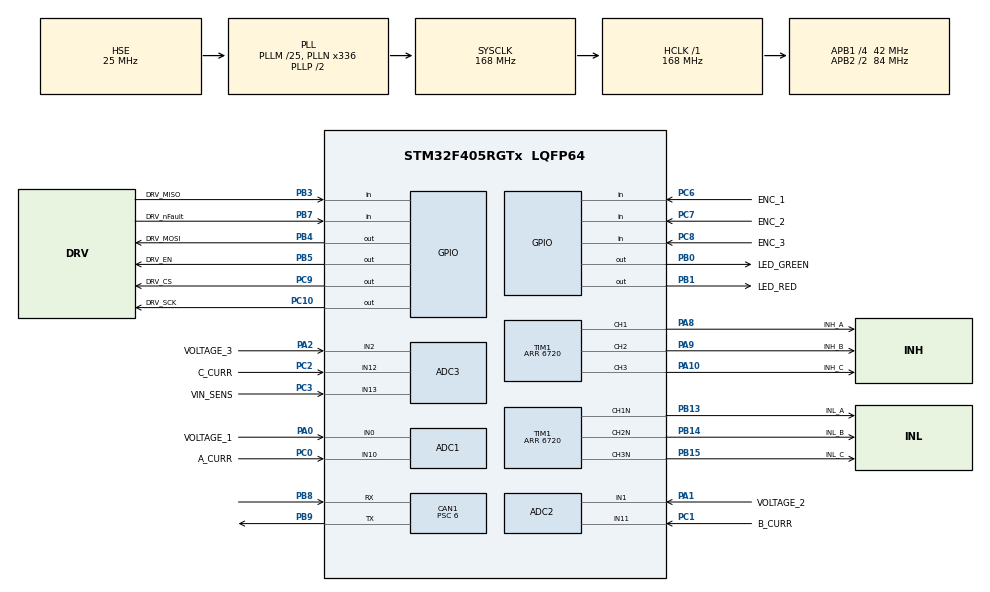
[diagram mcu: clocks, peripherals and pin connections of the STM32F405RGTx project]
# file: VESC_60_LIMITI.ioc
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ADC1.Channel-11\#ChannelInjectedConversion=ADC_CHANNEL_10
ADC1.Channel-12\#ChannelInjectedConversion=ADC_CHANNEL_10
ADC1.Channel-13\#ChannelRegularConversion=ADC_CHANNEL_VREFINT
ADC1.Channel-3\#ChannelRegularConversion=ADC_CHANNEL_10
ADC1.Channel-4\#ChannelRegularConversion=ADC_CHANNEL_0
ADC1.Channel-8\#ChannelInjectedConversion=ADC_CHANNEL_10
ADC1.ClockPrescaler=ADC_CLOCK_SYNC_PCLK_DIV6
ADC1.ExternalTrigConv=ADC_EXTERNALTRIGCONV_T2_CC2
ADC1.ExternalTrigConvEdge=ADC_EXTERNALTRIGCONVEDGE_FALLING
ADC1.InjNumberOfConversion=3
ADC1.InjectedOffset-11\#ChannelInjectedConversion=0
ADC1.InjectedOffset-12\#ChannelInjectedConversion=0
ADC1.InjectedOffset-8\#ChannelInjectedConversion=0
ADC1.InjectedRank-11\#ChannelInjectedConversion=2
ADC1.InjectedRank-12\#ChannelInjectedConversion=3
ADC1.InjectedRank-8\#ChannelInjectedConversion=1
ADC1.Mode=ADC_TRIPLEMODE_INJECSIMULT
ADC1.NbrOfConversion=3
ADC1.NbrOfConversionFlag=1
ADC1.Rank-13\#ChannelRegularConversion=3
ADC1.Rank-3\#ChannelRegularConversion=1
ADC1.Rank-4\#ChannelRegularConversion=2
ADC1.SamplingTime-11\#ChannelInjectedConversion=ADC_SAMPLETIME_3CYCLES
ADC1.SamplingTime-12\#ChannelInjectedConversion=ADC_SAMPLETIME_3CYCLES
ADC1.SamplingTime-13\#ChannelRegularConversion=ADC_SAMPLETIME_3CYCLES
ADC1.SamplingTime-3\#ChannelRegularConversion=ADC_SAMPLETIME_3CYCLES
ADC1.SamplingTime-4\#ChannelRegularConversion=ADC_SAMPLETIME_3CYCLES
ADC1.SamplingTime-8\#ChannelInjectedConversion=ADC_SAMPLETIME_3CYCLES
ADC1.ScanConvMode=ENABLE
ADC1.master=1
ADC2.Channel-0\#ChannelRegularConversion=ADC_CHANNEL_11
ADC2.Channel-1\#ChannelRegularConversion=ADC_CHANNEL_1
ADC2.Channel-5\#ChannelInjectedConversion=ADC_CHANNEL_11
ADC2.Channel-6\#ChannelInjectedConversion=ADC_CHANNEL_11
ADC2.ClockPrescaler=ADC_CLOCK_SYNC_PCLK_DIV6
ADC2.InjNumberOfConversion=2
ADC2.InjectedOffset-5\#ChannelInjectedConversion=0
ADC2.InjectedOffset-6\#ChannelInjectedConversion=0
ADC2.InjectedRank-5\#ChannelInjectedConversion=1
ADC2.InjectedRank-6\#ChannelInjectedConversion=2
ADC2.Mode=ADC_TRIPLEMODE_INJECSIMULT
ADC2.NbrOfConversion=2
ADC2.NbrOfConversionFlag=1
ADC2.Rank-0\#ChannelRegularConversion=1
ADC2.Rank-1\#ChannelRegularConversion=2
ADC2.SamplingTime-0\#ChannelRegularConversion=ADC_SAMPLETIME_3CYCLES
ADC2.SamplingTime-1\#ChannelRegularConversion=ADC_SAMPLETIME_3CYCLES
ADC2.SamplingTime-5\#ChannelInjectedConversion=ADC_SAMPLETIME_3CYCLES
ADC2.SamplingTime-6\#ChannelInjectedConversion=ADC_SAMPLETIME_3CYCLES
ADC3.Channel-0\#ChannelRegularConversion=ADC_CHANNEL_12
ADC3.Channel-1\#ChannelRegularConversion=ADC_CHANNEL_2
ADC3.Channel-5\#ChannelInjectedConversion=ADC_CHANNEL_12
ADC3.Channel-6\#ChannelInjectedConversion=ADC_CHANNEL_12
ADC3.Channel-7\#ChannelInjectedConversion=ADC_CHANNEL_12
ADC3.Channel-8\#ChannelRegularConversion=ADC_CHANNEL_13
ADC3.ClockPrescaler=ADC_CLOCK_SYNC_PCLK_DIV6
ADC3.InjNumberOfConversion=3
ADC3.InjectedOffset-5\#ChannelInjectedConversion=0
ADC3.InjectedOffset-6\#ChannelInjectedConversion=0
ADC3.InjectedOffset-7\#ChannelInjectedConversion=0
ADC3.InjectedRank-5\#ChannelInjectedConversion=1
ADC3.InjectedRank-6\#ChannelInjectedConversion=2
ADC3.InjectedRank-7\#ChannelInjectedConversion=3
ADC3.NbrOfConversion=3
ADC3.NbrOfConversionFlag=1
ADC3.Rank-0\#ChannelRegularConversion=1
ADC3.Rank-1\#ChannelRegularConversion=2
ADC3.Rank-8\#ChannelRegularConversion=3
ADC3.SamplingTime-0\#ChannelRegularConversion=ADC_SAMPLETIME_3CYCLES
ADC3.SamplingTime-1\#ChannelRegularConversion=ADC_SAMPLETIME_3CYCLES
ADC3.SamplingTime-5\#ChannelInjectedConversion=ADC_SAMPLETIME_3CYCLES
ADC3.SamplingTime-6\#ChannelInjectedConversion=ADC_SAMPLETIME_3CYCLES
ADC3.SamplingTime-7\#ChannelInjectedConversion=ADC_SAMPLETIME_3CYCLES
ADC3.SamplingTime-8\#ChannelRegularConversion=ADC_SAMPLETIME_3CYCLES
CAN1.BS1=CAN_BS1_4TQ
CAN1.BS2=CAN_BS2_2TQ
CAN1.CalculateBaudRate=1000000
CAN1.CalculateTimeBit=1000
CAN1.CalculateTimeQuantum=142.85714285714286
CAN1.Prescaler=6
Dma.ADC1.0.Direction=DMA_PERIPH_TO_MEMORY
Dma.ADC1.0.FIFOMode=DMA_FIFOMODE_DISABLE
Dma.ADC1.0.Instance=DMA2_Stream4
Dma.ADC1.0.MemDataAlignment=DMA_MDATAALIGN_HALFWORD
Dma.ADC1.0.MemInc=DMA_MINC_ENABLE
Dma.ADC1.0.Mode=DMA_CIRCULAR
Dma.ADC1.0.PeriphDataAlignment=DMA_PDATAALIGN_HALFWORD
Dma.ADC1.0.PeriphInc=DMA_PINC_DISABLE
Dma.ADC1.0.Priority=DMA_PRIORITY_HIGH
Dma.Request0=ADC1
FREERTOS.Tasks01=defaultTask,8,64,StartDefaultTask,Default,NULL,Dynamic,NULL,NULL;foc_pid,40,512,foc_pid_thread,Default,NULL,Dynamic,NULL,NULL;foc_sensor,32,256,foc_sensor_thread,Default,NULL,Dynamic,NULL,NULL;foc_comm,24,128,foc_comm_thread,Default,NULL,Dynamic,NULL,NULL
FREERTOS.configENABLE_FPU=1
FREERTOS.configMINIMAL_STACK_SIZE=64
FREERTOS.configTICK_RATE_HZ=1000
FREERTOS.configTOTAL_HEAP_SIZE=5360
Mcu.Family=STM32F4
Mcu.Name=STM32F405RGTx
Mcu.Package=LQFP64
NVIC.CAN1_RX0_IRQn=true\:5\:0\:false\:false\:true\:true\:true\:true\:true
NVIC.CAN1_TX_IRQn=true\:5\:0\:false\:false\:true\:true\:true\:true\:true
NVIC.DMA2_Stream4_IRQn=true\:5\:0\:false\:false\:true\:true\:false\:true\:true
NVIC.PriorityGroup=NVIC_PRIORITYGROUP_4
NVIC.TIM3_IRQn=true\:5\:0\:false\:false\:true\:true\:true\:true\:true
NVIC.TIM4_IRQn=true\:5\:0\:false\:false\:true\:true\:true\:true\:true
NVIC.TIM8_TRG_COM_TIM14_IRQn=true\:15\:0\:false\:false\:true\:false\:false\:true\:true
NVIC.TimeBase=TIM8_TRG_COM_TIM14_IRQn
NVIC.TimeBaseIP=TIM14
PA0-WKUP.GPIO_Label=VOLTAGE_1
PA0-WKUP.Signal=SharedAnalog_PA0
PA1.GPIO_Label=VOLTAGE_2
PA1.Signal=SharedAnalog_PA1
PA10.GPIO_Label=INH_C
PA10.Signal=S_TIM1_CH3
PA13.Mode=Serial_Wire
PA13.Signal=SYS_JTMS-SWDIO
PA14.Mode=Serial_Wire
PA14.Signal=SYS_JTCK-SWCLK
PA2.GPIO_Label=VOLTAGE_3
PA2.Signal=SharedAnalog_PA2
PA8.GPIO_Label=INH_A
PA8.Signal=S_TIM1_CH1
PA9.GPIO_Label=INH_B
PA9.Signal=S_TIM1_CH2
PB0.GPIO_Label=LED_GREEN
PB0.Signal=GPIO_Output
PB1.GPIO_Label=LED_RED
PB1.Signal=GPIO_Output
PB13.GPIO_Label=INL_A
PB13.Mode=PWM Generation1 CH1 CH1N
PB13.Signal=TIM1_CH1N
PB14.GPIO_Label=INL_B
PB14.Mode=PWM Generation2 CH2 CH2N
PB14.Signal=TIM1_CH2N
PB15.GPIO_Label=INL_C
PB15.Mode=PWM Generation3 CH3 CH3N
PB15.Signal=TIM1_CH3N
PB3.GPIO_Label=DRV_MISO
PB3.Signal=GPIO_Input
PB4.GPIO_Label=DRV_MOSI
PB4.Signal=GPIO_Output
PB5.GPIO_Label=DRV_EN
PB5.Signal=GPIO_Output
PB7.GPIO_Label=DRV_nFault
PB7.GPIO_PuPd=GPIO_PULLUP
PB7.Signal=GPIO_Input
PB8.Mode=CAN_Activate
PB8.Signal=CAN1_RX
PB9.Mode=CAN_Activate
PB9.Signal=CAN1_TX
PC0.GPIO_Label=A_CURR
PC0.Signal=ADCx_IN10
PC1.GPIO_Label=B_CURR
PC1.Signal=ADCx_IN11
PC10.GPIO_Label=DRV_SCK
PC10.Signal=GPIO_Output
PC2.GPIO_Label=C_CURR
PC2.Signal=ADCx_IN12
PC3.GPIO_Label=VIN_SENS
PC3.Signal=ADCx_IN13
PC6.GPIO_Label=ENC_1
PC6.GPIO_PuPd=GPIO_PULLUP
PC6.Signal=GPIO_Input
PC7.GPIO_Label=ENC_2
PC7.GPIO_PuPd=GPIO_PULLUP
PC7.Signal=GPIO_Input
PC8.GPIO_Label=ENC_3
PC8.GPIO_PuPd=GPIO_PULLUP
PC8.Signal=GPIO_Input
PC9.GPIO_Label=DRV_CS
PC9.Signal=GPIO_Output
PH0-OSC_IN.Mode=HSE-External-Oscillator
PH0-OSC_IN.Signal=RCC_OSC_IN
PH1-OSC_OUT.Mode=HSE-External-Oscillator
PH1-OSC_OUT.Signal=RCC_OSC_OUT
ProjectManager.HeapSize=0x200
ProjectManager.StackSize=0x400
ProjectManager.TargetToolchain=MDK-ARM V5.32
RCC.48MHZClocksFreq_Value=84000000
RCC.AHBFreq_Value=168000000
RCC.APB1CLKDivider=RCC_HCLK_DIV4
RCC.APB1Freq_Value=42000000
RCC.APB1TimFreq_Value=84000000
RCC.APB2CLKDivider=RCC_HCLK_DIV2
RCC.APB2Freq_Value=84000000
RCC.APB2TimFreq_Value=168000000
RCC.CortexFreq_Value=168000000
RCC.HCLKFreq_Value=168000000
RCC.HSE_VALUE=25000000
RCC.HSI_VALUE=16000000
RCC.LSE_VALUE=32768
RCC.PLLM=25
RCC.PLLN=336
RCC.PLLSourceVirtual=RCC_PLLSOURCE_HSE
RCC.SYSCLKFreq_VALUE=168000000
RCC.SYSCLKSource=RCC_SYSCLKSOURCE_PLLCLK
RCC.VCOOutputFreq_Value=336000000
SH.ADCx_IN10.0=ADC1_IN10,IN10
SH.ADCx_IN11.0=ADC2_IN11,IN11
SH.ADCx_IN12.0=ADC3_IN12,IN12
SH.ADCx_IN13.0=ADC3_IN13,IN13
SH.S_TIM1_CH1.0=TIM1_CH1,PWM Generation1 CH1 CH1N
SH.S_TIM1_CH2.0=TIM1_CH2,PWM Generation2 CH2 CH2N
SH.S_TIM1_CH3.0=TIM1_CH3,PWM Generation3 CH3 CH3N
SH.SharedAnalog_PA0.0=GPIO_Analog
SH.SharedAnalog_PA0.1=ADC1_IN0,IN0
SH.SharedAnalog_PA1.0=GPIO_Analog
SH.SharedAnalog_PA1.1=ADC2_IN1,IN1
SH.SharedAnalog_PA2.0=GPIO_Analog
SH.SharedAnalog_PA2.1=ADC3_IN2,IN2
TIM1.Channel-PWM\ Generation1\ CH1\ CH1N=TIM_CHANNEL_1
TIM1.Channel-PWM\ Generation2\ CH2\ CH2N=TIM_CHANNEL_2
TIM1.Channel-PWM\ Generation3\ CH3\ CH3N=TIM_CHANNEL_3
TIM1.CounterMode=TIM_COUNTERMODE_CENTERALIGNED1
TIM1.DeadTime=60
TIM1.OCIdleState_1=TIM_OCIDLESTATE_RESET
TIM1.OCIdleState_2=TIM_OCIDLESTATE_RESET
TIM1.OCIdleState_3=TIM_OCIDLESTATE_RESET
TIM1.OCNIdleState_1=TIM_OCNIDLESTATE_RESET
TIM1.OCNIdleState_2=TIM_OCNIDLESTATE_RESET
TIM1.OCNIdleState_3=TIM_OCNIDLESTATE_RESET
TIM1.OffStateIDLEMode=TIM_OSSI_ENABLE
TIM1.OffStateRunMode=TIM_OSSR_ENABLE
TIM1.Period=6720
TIM1.TIM_MasterOutputTrigger=TIM_TRGO_UPDATE
TIM1.TIM_MasterSlaveMode=TIM_MASTERSLAVEMODE_ENABLE
TIM2.AutoReloadPreload=TIM_AUTORELOAD_PRELOAD_ENABLE
TIM2.Channel-PWM\ Generation1\ No\ Output=TIM_CHANNEL_1
TIM2.Channel-PWM\ Generation2\ No\ Output=TIM_CHANNEL_2
TIM2.Channel-PWM\ Generation3\ No\ Output=TIM_CHANNEL_3
TIM2.Pulse-PWM\ Generation1\ No\ Output=250
TIM2.Pulse-PWM\ Generation2\ No\ Output=250
TIM2.Pulse-PWM\ Generation3\ No\ Output=250
TIM2.TIM_MasterSlaveMode=TIM_MASTERSLAVEMODE_ENABLE
TIM4.Period=100-1
TIM4.Prescaler=84-1
TIM5.Prescaler=6-1
VP_ADC1_Vref_Input.Mode=IN-Vrefint
VP_FREERTOS_VS_CMSIS_V2.Mode=CMSIS_V2
VP_SYS_VS_tim14.Mode=TIM14
VP_TIM1_VS_ClockSourceINT.Mode=Internal
VP_TIM2_VS_ClockSourceINT.Mode=Internal
VP_TIM2_VS_ClockSourceITR.Mode=TriggerSource_ITR0
VP_TIM2_VS_ControllerModeReset.Mode=Reset Mode
VP_TIM2_VS_no_output1.Mode=PWM Generation1 No Output
VP_TIM2_VS_no_output2.Mode=PWM Generation2 No Output
VP_TIM2_VS_no_output3.Mode=PWM Generation3 No Output
VP_TIM3_VS_ClockSourceINT.Mode=Internal
VP_TIM4_VS_ClockSourceINT.Mode=Internal
VP_TIM5_VS_ClockSourceINT.Mode=Internal
board=custom

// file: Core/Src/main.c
/* USER CODE BEGIN Header */
/**
  ******************************************************************************
  * @file           : main.c
  * @brief          : Main program body
  ******************************************************************************
  * @attention
  *
  * Copyright (c) 2025 STMicroelectronics.
  * All rights reserved.
  *
  * This software is licensed under terms that can be found in the LICENSE file
  * in the root directory of this software component.
  * If no LICENSE file comes with this software, it is provided AS-IS.
  *
  ******************************************************************************
  */
/* USER CODE END Header */
#include "main.h"
#include "cmsis_os.h"
#include "adc.h"
#include "can.h"
#include "dma.h"
#include "tim.h"
#include "gpio.h"

/* USER CODE BEGIN Includes */
#include "can_bsp.h"
#include "foc_interface.h"
/* USER CODE END Includes */

void SystemClock_Config(void);
void MX_FREERTOS_Init(void);

int main(void)
{

  /* MCU Configuration--------------------------------------------------------*/

  /* Reset of all peripherals, Initializes the Flash interface and the Systick. */
  HAL_Init();

  /* Configure the system clock */
  SystemClock_Config();

  /* Initialize all configured peripherals */
  MX_GPIO_Init();
  MX_DMA_Init();
  MX_ADC1_Init();
  MX_ADC2_Init();
  MX_ADC3_Init();
  MX_TIM3_Init();
  MX_TIM1_Init();
  MX_TIM2_Init();
  MX_CAN1_Init();
  MX_TIM5_Init();
  MX_TIM4_Init();
  /* USER CODE BEGIN 2 */
  // enc_as504x_init(&as5047_cfg);
  CAN_Init(&hcan1);
  foc_init();

  /* USER CODE END 2 */

  /* Init scheduler */
  osKernelInitialize();

  /* Call init function for freertos objects (in freertos.c) */
  MX_FREERTOS_Init();

  /* Start scheduler */
  osKernelStart();

  /* We should never get here as control is now taken by the scheduler */
  /* Infinite loop */
  while (1)
  {

  }
}

void SystemClock_Config(void)
{
  RCC_OscInitTypeDef RCC_OscInitStruct = {0};
  RCC_ClkInitTypeDef RCC_ClkInitStruct = {0};

  /** Configure the main internal regulator output voltage
  */
  __HAL_RCC_PWR_CLK_ENABLE();
  __HAL_PWR_VOLTAGESCALING_CONFIG(PWR_REGULATOR_VOLTAGE_SCALE1);

  /** Initializes the RCC Oscillators according to the specified parameters
  * in the RCC_OscInitTypeDef structure.
  */
  RCC_OscInitStruct.OscillatorType = RCC_OSCILLATORTYPE_HSE;
  RCC_OscInitStruct.HSEState = RCC_HSE_ON;
  RCC_OscInitStruct.PLL.PLLState = RCC_PLL_ON;
  RCC_OscInitStruct.PLL.PLLSource = RCC_PLLSOURCE_HSE;
  RCC_OscInitStruct.PLL.PLLM = 25;
  RCC_OscInitStruct.PLL.PLLN = 336;
  RCC_OscInitStruct.PLL.PLLP = RCC_PLLP_DIV2;
  RCC_OscInitStruct.PLL.PLLQ = 4;
  if (HAL_RCC_OscConfig(&RCC_OscInitStruct) != HAL_OK)
  {
    Error_Handler();
  }

  /** Initializes the CPU, AHB and APB buses clocks
  */
  RCC_ClkInitStruct.ClockType = RCC_CLOCKTYPE_HCLK|RCC_CLOCKTYPE_SYSCLK
                              |RCC_CLOCKTYPE_PCLK1|RCC_CLOCKTYPE_PCLK2;
  RCC_ClkInitStruct.SYSCLKSource = RCC_SYSCLKSOURCE_PLLCLK;
  RCC_ClkInitStruct.AHBCLKDivider = RCC_SYSCLK_DIV1;
  RCC_ClkInitStruct.APB1CLKDivider = RCC_HCLK_DIV4;
  RCC_ClkInitStruct.APB2CLKDivider = RCC_HCLK_DIV2;

  if (HAL_RCC_ClockConfig(&RCC_ClkInitStruct, FLASH_LATENCY_5) != HAL_OK)
  {
    Error_Handler();
  }
}

void HAL_TIM_PeriodElapsedCallback(TIM_HandleTypeDef *htim)
{
  /* USER CODE BEGIN Callback 0 */
  if (htim->Instance == TIM4) {
    interface_encoder_routine();
  }

  /* USER CODE END Callback 0 */
  if (htim->Instance == TIM14) {
    HAL_IncTick();
  }
}

void Error_Handler(void)
{
  __disable_irq();
  while (1)
  {
  }
}

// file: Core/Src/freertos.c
/* USER CODE BEGIN Header */
/**
  ******************************************************************************
  * File Name          : freertos.c
  * Description        : Code for freertos applications
  ******************************************************************************
  * @attention
  *
  * Copyright (c) 2025 STMicroelectronics.
  * All rights reserved.
  *
  * This software is licensed under terms that can be found in the LICENSE file
  * in the root directory of this software component.
  * If no LICENSE file comes with this software, it is provided AS-IS.
  *
  ******************************************************************************
  */
/* USER CODE END Header */

#include "FreeRTOS.h"
#include "task.h"
#include "main.h"
#include "cmsis_os.h"

/* USER CODE BEGIN Includes */
#include "foc_interface.h"
/* USER CODE END Includes */

/* Definitions for defaultTask */
osThreadId_t defaultTaskHandle;
const osThreadAttr_t defaultTask_attributes = {
  .name = "defaultTask",
  .stack_size = 64 * 4,
  .priority = (osPriority_t) osPriorityLow,
};
/* Definitions for foc_pid */
osThreadId_t foc_pidHandle;
const osThreadAttr_t foc_pid_attributes = {
  .name = "foc_pid",
  .stack_size = 512 * 4,
  .priority = (osPriority_t) osPriorityHigh,
};
/* Definitions for foc_sensor */
osThreadId_t foc_sensorHandle;
const osThreadAttr_t foc_sensor_attributes = {
  .name = "foc_sensor",
  .stack_size = 256 * 4,
  .priority = (osPriority_t) osPriorityAboveNormal,
};
/* Definitions for foc_comm */
osThreadId_t foc_commHandle;
const osThreadAttr_t foc_comm_attributes = {
  .name = "foc_comm",
  .stack_size = 128 * 4,
  .priority = (osPriority_t) osPriorityNormal,
};

void StartDefaultTask(void *argument);
void foc_pid_thread(void *argument);
void foc_sensor_thread(void *argument);
void foc_comm_thread(void *argument);

void MX_FREERTOS_Init(void); /* (MISRA C 2004 rule 8.1) */

void MX_FREERTOS_Init(void) {

  /* Create the thread(s) */
  /* creation of defaultTask */
  defaultTaskHandle = osThreadNew(StartDefaultTask, NULL, &defaultTask_attributes);

  /* creation of foc_pid */
  foc_pidHandle = osThreadNew(foc_pid_thread, NULL, &foc_pid_attributes);

  /* creation of foc_sensor */
  foc_sensorHandle = osThreadNew(foc_sensor_thread, NULL, &foc_sensor_attributes);

  /* creation of foc_comm */
  foc_commHandle = osThreadNew(foc_comm_thread, NULL, &foc_comm_attributes);

}

void StartDefaultTask(void *argument)
{
  for(;;)
  {
    osDelay(1);
  }
}

void foc_pid_thread(void *argument)
{
  /* USER CODE BEGIN foc_pid_thread */
  /* Infinite loop */
  for(;;)
  {
    interface_run_pid();
    osDelay(1);
  }
  /* USER CODE END foc_pid_thread */
}

void foc_sensor_thread(void *argument)
{
  for(;;)
  {
    osDelay(1);
  }
}

void foc_comm_thread(void *argument)
{
  for(;;)
  {
    osDelay(1);
  }
}
